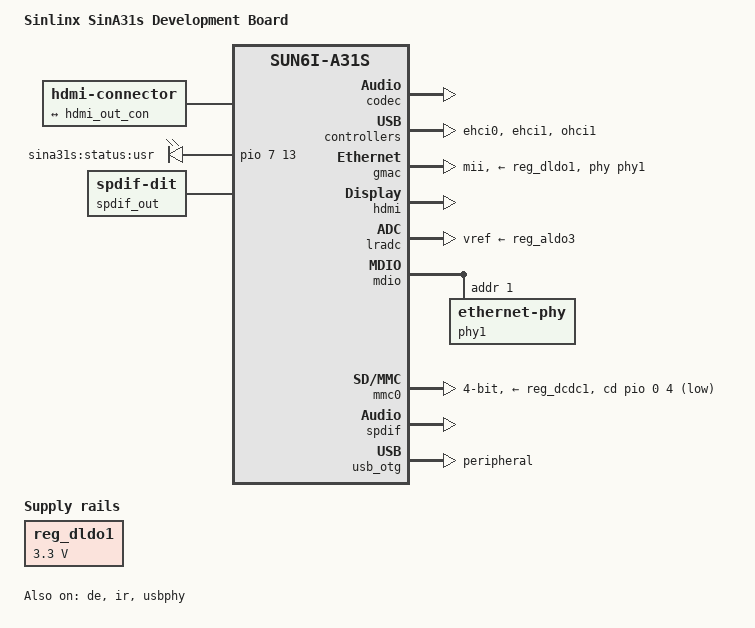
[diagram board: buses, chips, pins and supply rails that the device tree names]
#include "sun6i-a31s-sina31s-core.dtsi"
#include <dt-bindings/input/input.h>
/ {
	model = "Sinlinx SinA31s Development Board";
	compatible = "sinlinx,sina31s-sdk", "allwinner,sun6i-a31s";
	chosen {
		stdout-path = "serial0:115200n8";
	};
	hdmi-connector {
		compatible = "hdmi-connector";
		type = "a";
		port {
			hdmi_con_in: endpoint {
				remote-endpoint = <&hdmi_out_con>;
			};
		};
	};
	leds {
		compatible = "gpio-leds";
		led-0 {
			label = "sina31s:status:usr";
			gpios = <&pio 7 13 GPIO_ACTIVE_HIGH>;  
		};
	};
	sound {
		compatible = "simple-audio-card";
		simple-audio-card,name = "On-board SPDIF";
		simple-audio-card,cpu {
			sound-dai = <&spdif>;
		};
		simple-audio-card,codec {
			sound-dai = <&spdif_out>;
		};
	};
	spdif_out: spdif-out {
		#sound-dai-cells = <0>;
		compatible = "linux,spdif-dit";
	};
};
&codec {
	allwinner,audio-routing =
		"Line Out", "LINEOUT",
		"MIC1", "Mic",
		"Mic",	"MBIAS";
	status = "okay";
};
&de {
	status = "okay";
};
&ehci0 {
	status = "okay";
};
&ehci1 {
	status = "okay";
};
&gmac {
	pinctrl-names = "default";
	pinctrl-0 = <&gmac_mii_pins>;
	phy-handle = <&phy1>;
	phy-mode = "mii";
	phy-supply = <&reg_dldo1>;
	status = "okay";
};
&hdmi {
	status = "okay";
};
&hdmi_out {
	hdmi_out_con: endpoint {
		remote-endpoint = <&hdmi_con_in>;
	};
};
&ir {
	pinctrl-names = "default";
	pinctrl-0 = <&s_ir_rx_pin>;
	status = "okay";
};
&lradc {
	vref-supply = <&reg_aldo3>;
	status = "okay";
	button-158 {
		label = "Volume Up";
		linux,code = <KEY_VOLUMEUP>;
		channel = <0>;
		voltage = <158730>;
	};
	button-349 {
		label = "Volume Down";
		linux,code = <KEY_VOLUMEDOWN>;
		channel = <0>;
		voltage = <349206>;
	};
};
&mdio {
	phy1: ethernet-phy@1 {
		reg = <1>;
	};
};
&mmc0 {
	vmmc-supply = <&reg_dcdc1>;
	bus-width = <4>;
	cd-gpios = <&pio 0 4 GPIO_ACTIVE_LOW>;  
	status = "okay";
};
&ohci1 {
	status = "okay";
};
&reg_dldo1 {
	regulator-min-microvolt = <3300000>;
	regulator-max-microvolt = <3300000>;
	regulator-name = "vcc-gmac-phy";
};
&spdif {
	pinctrl-names = "default";
	pinctrl-0 = <&spdif_tx_pin>;
	status = "okay";
};
&usb_otg {
	dr_mode = "peripheral";
	status = "okay";
};
&usbphy {
	status = "okay";
};
